VERSION ""

NS_ :

BS_:

BU_: PC

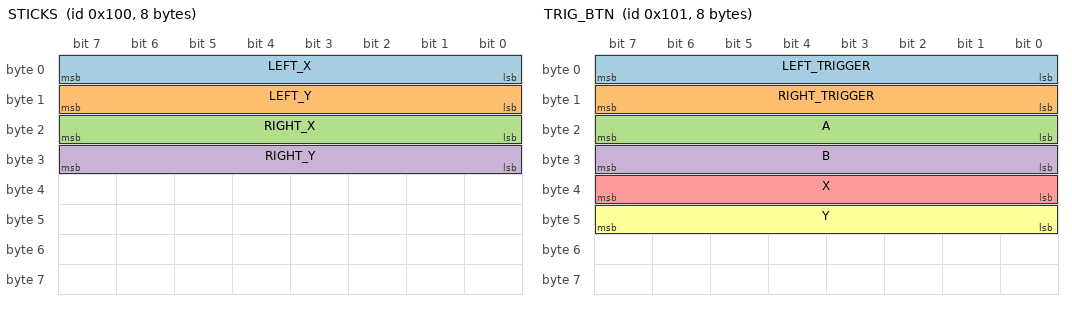
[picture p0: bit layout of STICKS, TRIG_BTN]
BO_ 256 STICKS: 8 PC
 SG_ LEFT_X : 0|8@1+ (1,0) [0|255] ""  PC
 SG_ LEFT_Y : 8|8@1+ (1,0) [0|255] ""  PC
 SG_ RIGHT_X : 16|8@1+ (1,0) [0|255] ""  PC
 SG_ RIGHT_Y : 24|8@1+ (1,0) [0|255] ""  PC

BO_ 257 TRIG_BTN: 8 PC
 SG_ LEFT_TRIGGER : 0|8@1+ (1,0) [0|255] ""  PC
 SG_ RIGHT_TRIGGER : 8|8@1+ (1,0) [0|255] ""  PC
 SG_ A : 16|8@1+ (1,0) [0|1] ""  PC
 SG_ B : 24|8@1+ (1,0) [0|1] ""  PC
 SG_ X : 32|8@1+ (1,0) [0|1] ""  PC
 SG_ Y : 40|8@1+ (1,0) [0|1] ""  PC

BO_ 258 CURVE: 8 PC
 SG_ CURVE_RADIUS : 0|32@1- (1,0) [0|10000] "m"  PC
 SG_ CURVATURE : 32|32@1- (1,0) [0|1] "1/m"  PC

SIG_VALTYPE_ 258 CURVE_RADIUS : 1;
SIG_VALTYPE_ 258 CURVATURE : 1;
